# RTS5918 register map
Vendor: Realtek Semiconductor Corp.; Series: RTS5918 Series; File version: 1.00
CPU: ARMV8MML r0p0, little endian, MPU, FPU, VTOR, 3 interrupt priority bits, 8 SAU regions
Registers are 32-bit, read-write, reset 0x0 unless marked. A register's access mark holds for its fields unless they carry their own. Offsets are from the block's base; [hi:lo] are bit positions; {n}, {i} and the like mark numbered series; 'fields as' and 'values as' point back to an identical list.

## I2C0 — I2C Controller
Base 0x40250000
Same registers: I2C{n} {0x40250000+0x200*n} (n=1..10)
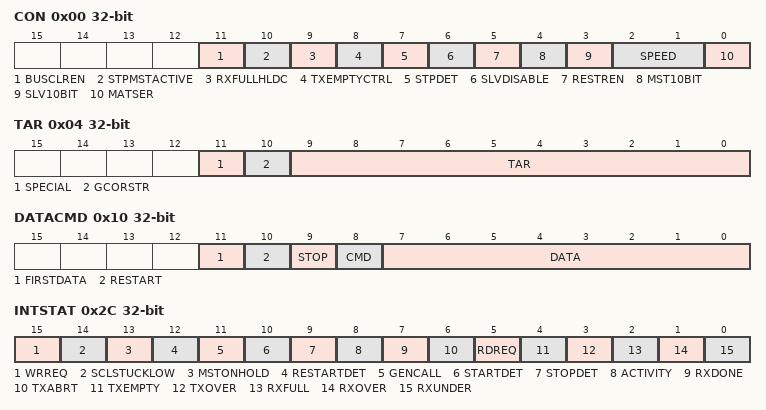
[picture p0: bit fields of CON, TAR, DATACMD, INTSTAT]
0x00 CON — CONTROL REGISTER
  [11] BUSCLREN — Enables the Bus Clear Feature
    0=DISABLE (Bus Clear Feature is enabled); 1=ENABLE (Bus Clear Feature is disabled)
  [10] STPMSTACTIVE — How I2c Controller Issues The Stop Detection Interrupt
    0=DISABLE (Master issues the stop detection interrupt irrespective of whether master is active or not); 1=ENABLE (Master issues the stop detection interrupt only when master is active)
  [9] RXFULLHLDC — Hold the Bus When The Rx FIFO Is Full Or Not
    0=DISABLE (Overflow when RX FIFO is full); 1=ENABLE (Hold bus when RX FIFO is full)
  [8] TXEMPTYCTRL — Controls the Generation Of The Tx Empty Interrupt
    0=DISABLE (Default behaviour of tx empty interrupt); 1=ENABLE (Controlled generation of tx empty interrupt)
  [7] STPDET — How Slave Issues Stop Detection Interrupt
    0=ALWAYS (Slave issues stop detection interrupt always); 1=ADDRESSED (Slave issues stop detection interrupt only if addressed)
  [6] SLVDISABLE — Enable/Disable Slave Mode
    0=Enable slave mode; 1=Disable slave mode
  [5] RESTREN — Enable/Disable Master Restart
    0=DISABLE (Master restart disabled); 1=ENABLE (Master restart enabled)
  [4] MST10BIT — Master Is 7-bit Or 10-bit Addressing Mode
    0=7_BIT (Master 7-bit addressing); 1=10_BIT (Master 10-bit addressing)
  [3] SLV10BIT — Slave Responds To 7-bit Or 10-bit Addresses
    0=7_BIT (Slave 7-bit addressing); 1=10_BIT (Slave 10-bit addressing)
  [2:1] SPEED — Speed Mode
    0=NONE (Not defined); 1=STANDARD (Standard speed); 2=FAST (Fast speed); 3=HIGH (High speed)
  [0] MATSER — Enable/Disable Master Mode
    0=DISABLE (Master mode is disabled); 1=ENABLE (Master mode is enabled)
0x04 TAR — TARGET ADDRESS REGISTER
  [11] SPECIAL — Indicates Whether Software Performs A Device-id Or General Call Or Start Byte Command
    0=DISABLE (Disables programming of GENERAL_CALL or START_BYTE transmission); 1=ENABLE (Enables programming of GENERAL_CALL or START_BYTE transmission)
  [10] GCORSTR — Indicates Whether A General Call Or Start Byte Command
    0=GEN_CALL (General Call byte transmission); 1=START (START byte transmission)
  [9:0] TAR — Target Address For Any Master Transaction
0x08 SAR — SLAVE ADDRESS REGISTER
  [9:0] SAR — Holds The Slave Address When The I2c Is Operating As A Slave
0x10 DATACMD — DATA BUFFER AND COMMAND REGISTER
  [11] FIRSTDATA ro — Indicates The First Data Byte Received After The Address Phase
    0=INACTIVE (Non sequential data byte received); 1=ACTIVE (Sequential data byte received)
  [10] RESTART wo — Controls Whether a RESTART Is Issued Before The Byte Is Sent Or Received
    0=DISABLE (Do not Issue RESTART before this command); 1=ENABLE (Issue RESTART before this command)
  [9] STOP wo — Controls Whether A Stop Is Issued After The Byte Is Sent Or Received
    0=DISABLE (Do not issue STOP after this command); 1=ENABLE (Issue STOP after this command)
  [8] CMD wo — Controls Whether A Read Or A Write Is Performed
    0=WRITE (Master write command); 1=READ (Master read command)
  [7:0] DATA — The Data To Be Transmitted Or Received On The I2C Bus
0x14 SCLHCNT — STANDARD SPEED I2C CLOCK SCL HIGH COUNT REGISTER
  [15:0] HCNT — Sets the SCL Clock High-period Count For Standard Speed
0x18 SCLLCNT — STANDARD SPEED I2C CLOCK SCL LOW COUNT REGISTER
  [15:0] LCNT — Sets the SCL Clock Low-period Count For Standard Speed
0x1C FSSCLHCNT — FAST MODE SCL HIGH COUNT REGISTER
  [15:0] HCNT — Sets the SCL Clock High-period Count For Fast Speed
0x20 FSSCLLCNT — FAST MODE SCL LOW COUNT REGISTER
  [15:0] LCNT — Sets the SCL Clock Low-period Count For Fast Speed
0x2C INTSTAT ro — I2C INTERRUPT STATUS REGISTER
  [15] WRREQ — WR_REQ Interrupt
    0=INACTIVE (WR_REQ interrupt is inactive); 1=ACTIVE (WR_REQ interrupt is active)
  [14] SCLSTUCKLOW — SCL_STUCK_AT_LOW Interrupt
    0=INACTIVE (SCL_STUCK_AT_LOW interrupt is inactive); 1=ACTIVE (SCL_STUCK_AT_LOW interrupt is active)
  [13] MSTONHOLD — MASTER_ON_HOLD Interrupt
    0=INACTIVE (MASTER_ON_HOLD interrupt is inactive); 1=ACTIVE (MASTER_ON_HOLD interrupt is active)
  [12] RESTARTDET — RESTART_DET Interrupt
    0=INACTIVE (RESTART_DET interrupt is inactive); 1=ACTIVE (RESTART_DET interrupt is active)
  [11] GENCALL — GEN_CALL Interrupt
    0=INACTIVE (GEN-CALL interrupt is inactive); 1=ACTIVE (GEN-CALL interrupt is active)
  [10] STARTDET — START_DET Interrupt
    0=INACTIVE (START_DET interrupt is inactive); 1=ACTIVE (START_DET interrupt is active)
  [9] STOPDET — STOP_DET Interrupt
    0=INACTIVE (STOP_DET interrupt is inactive); 1=ACTIVE (STOP_DET interrupt is active)
  [8] ACTIVITY — ACTIVITY Interrupt
    0=INACTIVE (ACTIVITY interrupt is inactive); 1=ACTIVE (ACTIVITY interrupt is active)
  [7] RXDONE — RX_DONE Interrupt
    0=INACTIVE (RX_DONE interrupt is inactive); 1=ACTIVE (RX_DONE interrupt is active)
  [6] TXABRT — TX_ABRT Interrupt
    0=INACTIVE (TX_ABRT interrupt is inactive); 1=ACTIVE (TX_ABRT interrupt is active)
  [5] RDREQ — RD_REQ interrupt
    0=INACTIVE (RD_REQ interrupt is inactive); 1=ACTIVE (RD_REQ interrupt is active)
  [4] TXEMPTY — TX_EMPTY Interrupt
    0=INACTIVE (TX_EMPTY interrupt is inactive); 1=ACTIVE (TX_EMPTY interrupt is active)
  [3] TXOVER — TX_OVER Interrupt
    0=INACTIVE (TX_OVER interrupt is inactive); 1=ACTIVE (TX_OVER interrupt is active)
  [2] RXFULL — RX_FULL Interrupt
    0=INACTIVE (RX_FULL interrupt is inactive); 1=ACTIVE (RX_FULL interrupt is active)
  [1] RXOVER — RX_OVER Interrupt
    0=INACTIVE (RX_OVER interrupt is inactive); 1=ACTIVE (RX_OVER interrupt is active)
  [0] RXUNDER — RX_UNDER Interrupt
    0=INACTIVE (RX_UNDER interrupt is inactive); 1=ACTIVE (RX_UNDER interrupt is active)
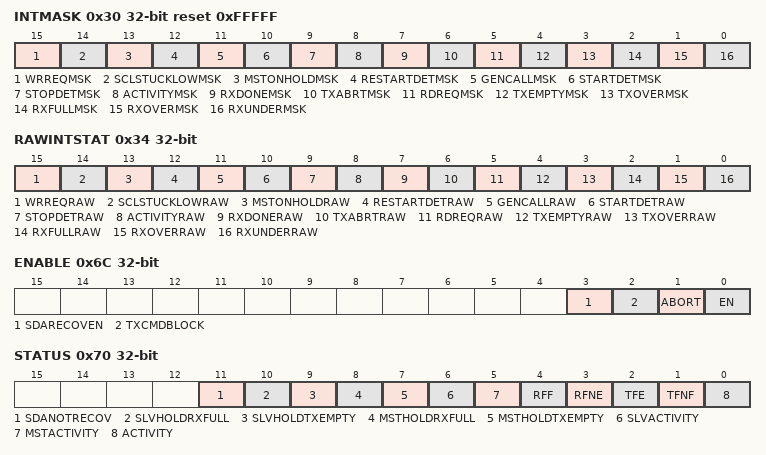
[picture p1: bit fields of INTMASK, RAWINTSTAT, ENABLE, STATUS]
0x30 INTMASK reset 0xFFFFF — INTERRUPT MASK REGISTER
  [15] WRREQMSK — WR_REQ Interrupt Mask
    1=UNMASKED (WR_REQ interrupt is unmasked); 0=MASKED (WR_REQ interrupt is masked)
  [14] SCLSTUCKLOWMSK — SCL_STUCK_AT_LOW Interrupt Mask
    1=UNMASKED (SCL_STUCK_AT_LOW interrupt is unmasked); 0=MASKED (SCL_STUCK_AT_LOW interrupt is masked)
  [13] MSTONHOLDMSK — MASTER_ON_HOLD Interrupt Mask
    1=UNMASKED (MASTER_ON_HOLD interrupt is unmasked); 0=MASKED (MASTER_ON_HOLD interrupt is masked)
  [12] RESTARTDETMSK — RESTART_DET Interrupt Mask
    1=UNMASKED (RESTART_DET interrupt is unmasked); 0=MASKED (RESTART_DET interrupt is masked)
  [11] GENCALLMSK — GEN_CALL Interrupt Mask
    1=UNMASKED (GEN-CALL interrupt is unmasked); 0=MASKED (GEN-CALL interrupt is masked)
  [10] STARTDETMSK — START_DET Interrupt Mask
    1=UNMASKED (START_DET interrupt is unmasked); 0=MASKED (START_DET interrupt is masked)
  [9] STOPDETMSK — STOP_DET Interrupt Mask
    1=UNMASKED (STOP_DET interrupt is unmasked); 0=MASKED (STOP_DET interrupt is masked)
  [8] ACTIVITYMSK — ACTIVITY Interrupt Mask
    1=UNMASKED (ACTIVITY interrupt is unmasked); 0=MASKED (ACTIVITY interrupt is masked)
  [7] RXDONEMSK — RX_DONE Interrupt Mask
    1=UNMASKED (RX_DONE interrupt is unmasked); 0=MASKED (RX_DONE interrupt is masked)
  [6] TXABRTMSK — TX_ABRT Interrupt Mask
    1=UNMASKED (TX_ABRT interrupt is unmasked); 0=MASKED (TX_ABRT interrupt is masked)
  [5] RDREQMSK — RD_REQ Interrupt Mask
    1=UNMASKED (RD_REQ interrupt is unmasked); 0=MASKED (RD_REQ interrupt is masked)
  [4] TXEMPTYMSK — TX_EMPTY Interrupt Mask
    1=UNMASKED (TX_EMPTY interrupt is unmasked); 0=MASKED (TX_EMPTY interrupt is masked)
  [3] TXOVERMSK — TX_OVER Interrupt Mask
    1=UNMASKED (TX_OVER interrupt is unmasked); 0=MASKED (TX_OVER interrupt is masked)
  [2] RXFULLMSK — RX_FULL Interrupt Mask
    1=UNMASKED (RX_FULL interrupt is unmasked); 0=MASKED (RX_FULL interrupt is masked)
  [1] RXOVERMSK — RX_OVER Interrupt Mask
    1=UNMASKED (RX_OVER interrupt is unmasked); 0=MASKED (RX_OVER interrupt is masked)
  [0] RXUNDERMSK — RX_UNDER Interrupt Mask
    1=UNMASKED (RX_UNDER interrupt is unmasked); 0=MASKED (RX_UNDER interrupt is masked)
0x34 RAWINTSTAT — INTERRUPT STATUS REGISTER
  [15] WRREQRAW ro — WR_REQ Interrupt Status
    values as INTSTAT.WRREQ
  [14] SCLSTUCKLOWRAW ro — SCL_STUCK_AT_LOW Interrupt Status
    values as INTSTAT.SCLSTUCKLOW
  [13] MSTONHOLDRAW ro — MASTER_ON_HOLD Interrupt Status
    values as INTSTAT.MSTONHOLD
  [12] RESTARTDETRAW ro — RESTART_DET Interrupt Status
    values as INTSTAT.RESTARTDET
  [11] GENCALLRAW ro — GEN_CALL Interrupt Status
    values as INTSTAT.GENCALL
  [10] STARTDETRAW ro — START_DET Interrupt Status
    values as INTSTAT.STARTDET
  [9] STOPDETRAW ro — STOP_DET Interrupt Status
    values as INTSTAT.STOPDET
  [8] ACTIVITYRAW ro — I2C Controller Activity
    0=INACTIVE (RAW_INTR_ACTIVITY interrupt is inactive); 1=ACTIVE (RAW_INTR_ACTIVITY interrupt is active)
  [7] RXDONERAW ro — RX_DONE Interrupt Status
    values as INTSTAT.RXDONE
  [6] TXABRTRAW ro — TX_ABRT Interrupt Status
    values as INTSTAT.TXABRT
  [5] RDREQRAW ro — RD_REQ Interrupt Status
    values as INTSTAT.RDREQ
  [4] TXEMPTYRAW ro — TX_EMPTY Interrupt Status
    values as INTSTAT.TXEMPTY
  [3] TXOVERRAW ro — TX_OVER Interrupt Status
    values as INTSTAT.TXOVER
  [2] RXFULLRAW ro — RX_UNDER Interrupt Status
    values as INTSTAT.RXFULL
  [1] RXOVERRAW ro — RX_UNDER Interrupt Status
    values as INTSTAT.RXOVER
  [0] RXUNDERRAW ro — RX_UNDER Interrupt Status
    values as INTSTAT.RXUNDER
0x38 RXTL — I2C RECEIVE FIFO THRESHOLD REGISTER
  [7:0] THRES — Receive FIFO Threshold Level
0x3C TXTL — I2C TRANSMIT FIFO THRESHOLD REGISTER
  [7:0] THRES — Transmit FIFO Threshold Level
0x40 CLRINT ro — CLEAR COMBINED AND INDIVIDUAL INTERRUPT REGISTER
0x44 CLRRXUNDER ro — Clear RX_UNDER Interrupt
0x48 CLRRXOVER ro — Clear RX_OVER Interrupt Register
0x4C CLRTXOVER ro — Clear TX_OVER Interrupt Register
0x50 CLRRDREQ ro — Clear RD_REQ Interrupt Register
0x54 CLRTXABRT ro — Clear TX_ABRT Interrupt Register
0x58 CLRRXDONE ro — Clear RX_DONE Interrupt Register
0x5C CLRACTIVITY ro — Clear ACTIVITY Interrupt Register
0x60 CLRSTOPDET ro — Clear STOP_DET Interrupt Register
0x64 CLRSTARTDET ro — Clear START_DET Interrupt Register
0x68 CLRGENCALL ro — Clear GEN_CALL Interrupt Register
0x6C ENABLE
  [3] SDARECOVEN — Control Knob To Initiate The SDA Recovery Mechanism
    0=DISABLE (Master disabled the SDA stuck at low recovery mechanism); 1=ENABLE (Master initiates the SDA stuck at low recovery mechanism)
  [2] TXCMDBLOCK — Blocks The Transmission Of Data On I2c Bus Or Not
    0=DISABLE (The transmission of data starts on I2C bus automatically); 1=ENABLE (Blocks the transmission of data on I2C bus even if Tx FIFO has data to transmit)
  [1] ABORT — Initiates The Transfer Abort
    0=DISABLE (ABORT operation not in progress); 1=ENABLE (ABORT operation in progress)
  [0] EN — Controls Whether The I2C Controller Is Enabled
    0=DISABLE (Disables I2C controller); 1=ENABLE (Enable I2C controller)
0x70 STATUS ro — I2C STATUS Register
  [11] SDANOTRECOV — Indicates That SDA Stuck At Low Is Not Recovered After The Recovery Mechanism
    0=Inactive (SDA Stuck at low is recovered after recovery mechanism); 1=Active (SDA Stuck at low is not recovered after recovery mechanism)
  [10] SLVHOLDRXFULL — Indicates The Bus Hold In Slave Mode Due To Rx FIFO Is Full And Additional Byte Has Been Received
    0=Inactive (Slave is not holding the bus or Bus hold is not due to Rx FIFO is full); 1=Active (Slave holds the bus due to Rx FIFO is full)
  [9] SLVHOLDTXEMPTY — Indicates The Bus Hold In Slave Mode Due To Rx FIFO Is Full And Additional Byte Has Been Received
    0=INACTIVE (Slave is not holding the bus or Bus hold is not due to Rx FIFO is full); 1=ACTIVE (Slave holds the bus due to Rx FIFO is full)
  [8] MSTHOLDRXFULL — INdicates The Bus Hold In Master Mode Due To Rx FIFO Is Full And Additional Byte Has Been Received
    0=INACTIVE (Master is not holding the bus or Bus hold is not due to Rx FIFO is full); 1=ACTIVE (Master holds the bus due to Rx FIFO is full)
  [7] MSTHOLDTXEMPTY — Indicates The Bus Hold When The Master Holds The Bus Because Of The Tx FIFO Being Empty
    0=INACTIVE (Master holds the bus due to Tx FIFO is empty); 1=ACTIVE (Master is not holding the bus or Bus hold is not due to Tx FIFO is empty)
  [6] SLVACTIVITY — Slave FSM Activity Status
    0=IDLE (Slave is idle); 1=ACTIVE (Slave not idle)
  [5] MSTACTIVITY — Master FSM Activity Status
    0=IDLE (Master is idle); 1=ACTIVE (Master not idle)
  [4] RFF — Receive FIFO Completely Full
    0=NOTFULL (Rx FIFO not full); 1=FULL (Rx FIFO is full)
  [3] RFNE — Receive FIFO Not Empty
    0=EMPTY (Rx FIFO is empty); 1=NOTEMPTY (Rx FIFO not empty)
  [2] TFE — Transmit FIFO Completely Empty
    0=NOTEMPTY (Tx FIFO not empty); 1=EMPTY (Tx FIFO is empty)
  [1] TFNF — Transmit FIFO Not Full
    0=FULL (Tx FIFO is full); 1=NOTFULL (Tx FIFO not full)
  [0] ACTIVITY — I2C Activity Status
    0=INACTIVE (I2C is idle); 1=ACTIVE (I2C is active)
0x74 TXFLR — I2C TRANSMIT FIFO LEVEL REGISTER
0x78 RXFLR — I2C RECEIVE FIFO LEVEL REGISTER
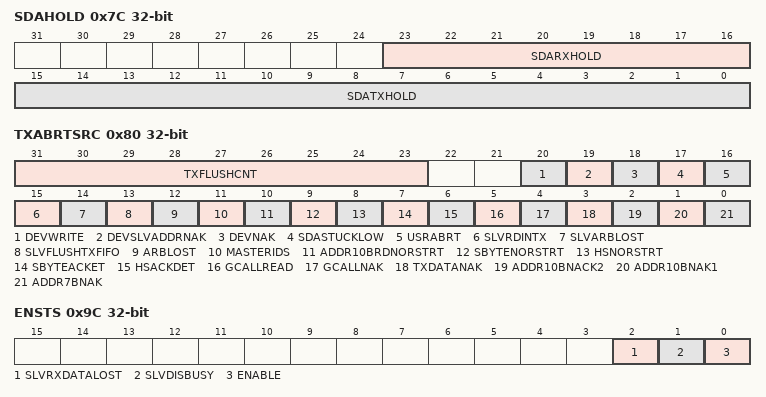
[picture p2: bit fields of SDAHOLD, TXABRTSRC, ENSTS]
0x7C SDAHOLD — I2C SDA HOLD TIME LENGTH REGISTER
  [23:16] SDARXHOLD — Sets the required SDA hold time in units of I2C clk period
  [15:0] SDATXHOLD — Sets The Required SDA Hold Time In Units Of clk Period
0x80 TXABRTSRC — I2C TRANSMIT ABORT SOURCE REGISTER
  [31:23] TXFLUSHCNT ro — Indicates The Number Of Tx FIFO Data Commands Which Are Flushed Due To TX_ABRT Interrupt
  [20] DEVWRITE ro — Master Is Initiating The DEVICE_ID Transfer And The Tx-FIFO Consists Of Write Commands
    0=NOTABORT (This abort is not generated); 1=ABORT (This abort is generated because of NOACK for Slave address)
  [19] DEVSLVADDRNAK ro — Master Is Initiating The DEVICE_ID Transfer And The Slave Address Sent Was Not Acknowledged By Any Slave
    values as DEVWRITE
  [18] DEVNAK ro — Master Is Initiating The DEVICE_ID Transfer And The Device Id Sent Was Not Acknowledged By Any Slave
    0=NOTABORT (This abort is not generated); 1=ABORT (This abort is generated because of NOACK for DEVICE-ID)
  [17] SDASTUCKLOW ro — This Is A Master-mode-only Bit. Master Detects The SDA Stuck At Low
    0=NOTABORT (This abort is not generated); 1=ABORT (This abort is generated because of SDA stuck at low)
  [16] USRABRT ro — This Is A Master-mode-only Bit. Master Has Detected The Transfer Abort
    0=NOTABORT (Transfer abort detected by master- scenario not present); 1=ABORT (Transfer abort detected by master)
  [15] SLVRDINTX ro — When The Processor Side Responds To A Slave Mode Request For Data To Be Transmitted To A Remote Master And User Writes A 1 In Cmd (bit 8) Of Ic_data_cmd Register
    0=NOTABORT (Slave trying to transmit to remote master in read mode- scenario not present); 1=ABORT (Slave trying to transmit to remote master in read mode)
  [14] SLVARBLOST ro — This Field Indicates That A Slave Has Lost The Bus While Transmitting Data To A Remote Master
    0=NOTLOST (Slave lost arbitration to remote master- scenario not present); 1=LOST (Slave lost arbitration to remote master)
  [13] SLVFLUSHTXFIFO ro — This Field Specifies That The Slave Has Received A Read Command And Some Data Exists In The TX FIFO
    0=NONABORT (Slave flushes existing data in TX-FIFO upon getting read commandscenario not present); 1=ABORT (Slave flushes existing data in TX-FIFO upon getting read command)
  [12] ARBLOST ro — This Field Specifies That The Master Has Lost Arbitration
    0=NOTLOST (Master or Slave-Transmitter lost arbitration- scenario not present); 1=LOST (Master or Slave-Transmitter lost arbitration)
  [11] MASTERIDS ro — Indicates That The User Tries To Initiate A Master Operation With The Master Mode Disabled
    0=NONABORT (User initiating master operation when MASTER disabled- scenario not present); 1=ABORT (User initiating master operation when MASTER disabled)
  [10] ADDR10BRDNORSTRT ro — Indicates That The Restart Is Disabled
    0=NONABORT (Master not trying to read in 10Bit addressing mode when RESTART disabled); 1=ABORT (Master trying to read in 10Bit addressing mode when RESTART disabled)
  [9] SBYTENORSTRT ro — Indicates That The Restart Is Disabled
    0=NONABORT (User trying to send START byte when RESTART disabled- scenario not present); 1=ABORT (User trying to send START byte when RESTART disabled)
  [8] HSNORSTRT ro — Indicates That The Restart Is Disabled
    0=NONABORT (User trying to switch Master to HS mode when RESTART disabled- scenario not present); 1=ABORT (User trying to switch Master to HS mode when RESTART disabled)
  [7] SBYTEACKET ro — Indicates That The Master Has Sent A START Byte And The START Byte Was Acknowledged
    0=NACK (ACK detected for START byte- scenario not present); 1=ACK (ACK detected for START byte)
  [6] HSACKDET ro — Indicates That The Master Is In High Speed Mode And The High Speed Master Code Was Acknowledged
    0=NACK (HS Master code ACKed in HS Mode- scenario not present); 1=ACK (HS Master code ACKed in HS Mode)
  [5] GCALLREAD ro — Indicates That Dw_apb_i2c In The Master Mode Has Sent A General Call But The User Programmed The Byte Following The General Call To Be A Read From The Bus
    0=NONABORT (GCALL is followed by read from bus-scenario not present); 1=ABORT (GCALL is followed by read from bus)
  [4] GCALLNAK ro — Indicates That I2C Controller In Master Mode Has Sent A General Call And No Slave On The Bus Acknowledged The General Call
    0=NACK (GCALL not ACKed by any slave-scenario not present); 1=ACK (GCALL not ACKed by any slave)
  [3] TXDATANAK ro — Indicates The Master-mode Only Bit. When Themaster Receives An Acknowledgement For The Address
    0=NACK (Transmitted data non-ACKed by addressed slave-scenario not present); 1=ACK (Transmitted data not ACKed by addressed slave)
  [2] ADDR10BNACK2 ro — Indicates That The Master Is In 10-bit Address Mode And The Second 10-bit Address Byte Was Not Acknowledged By Any Slave
    0=INACTIVE (This abort is not generated); 1=ACTIVE (Byte 2 of 10Bit Address not ACKed by any slave)
  [1] ADDR10BNAK1 ro — Indicates That The Master Is In 10-bit Address Mode And The First 10-bit Address Byte Was Not Acknowledged By Any Slave
    0=INACTIVE (This abort is not generated); 1=ACTIVE (Byte 1 of 10Bit Address not ACKed by any slave)
  [0] ADDR7BNAK ro — Indicates That The Master Is In 7-bit Addressing Mode And The Address Sent Was Not Acknowledged By Any Slave
    0=INACTIVE (This abort is not generated); 1=ACTIVE (This abort is generated because of NOACK for 7-bit address)
0x84 SLVDATANACKONLY — GENERATE SLAVE DATA NACK REGISTER
  [0] NAK — Generate Nack. This Nack Generation Only Occurs When I2C Controller Is A Slave-receiver
    0=DISABLE (Slave receiver generates NACK normally); 1=ENABLE (Slave receiver generates NACK upon data reception only)
0x94 SDASETUP — I2C SDA SETUP REGISTER
  [7:0] SETUP — SDA Setup (tSU:DAT)
0x98 ACKGENCALL — I2C ACK GENERAL CALL REGISTER
  [0] ACK — ACK General Call
    0=NACK (Generate NACK for General Call); 1=ACK (Generate ACK for a General Call)
0x9C ENSTS ro — I2C ENABLE STATUS REGISTER
  [2] SLVRXDATALOST — Slave Received Data Lost
    0=DISABLE (Slave RX Data is not lost); 1=ENABLE (Slave RX Data is lost)
  [1] SLVDISBUSY — Slave Disabled While Busy (Transmit, Receive)
    0=DISABLE (Slave is disabled when it is idle); 1=ENABLE (Slave is disabled when it is active)
  [0] ENABLE — IC Enable Status
    0=DISABLE (I2C disabled); 1=ENABLE (I2C enabled)
0xA0 SPKLEN — I2C SS, FS OR FM+ RO UFM SPIKE SUPPRESSION LIMIT
  [7:0] LEN — Sets the Duration, Measured In Clk Cycle
0xA8 CLRRESTARTDET — CLEAR RESTART_DET INTERRUPT REGISTER
0xAC SCLLOWTO — I2C SCL STUCK AT LOW TIMEOUT REGISTER
0xB0 SDALOWTO — I2C SDA STUCK AT LOW TIMEOUT REGISTER
0xB4 CLRSCLSTUCKDET — CLEAR SCL STUCK AT LOW DETECT INTERRUPT REGISTER
